# NUC100BN_v1 register map
File version: 1.0
Registers are 32-bit, read-write, reset 0x0 unless marked. A register's access mark holds for its fields unless they carry their own. Offsets are from the block's base; [hi:lo] are bit positions; 'fields as' and 'values as' point back to an identical list.

## SPI0 — SPI Register Map
Base 0x40030000
Same registers: SPI1 0x40034000, SPI2 0x40130000, SPI3 0x40134000
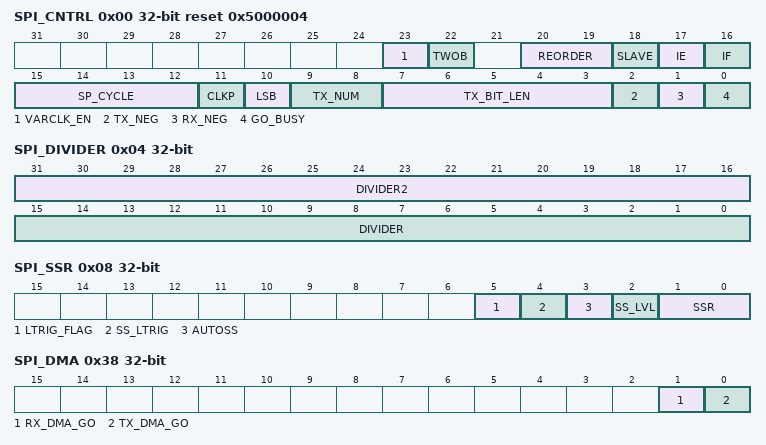
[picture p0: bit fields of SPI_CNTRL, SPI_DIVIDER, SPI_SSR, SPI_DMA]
0x00 SPI_CNTRL reset 0x5000004 — Control and Status Register
  [23] VARCLK_EN — Variable Clock Enable (Master Only). Note: When this VARCLK_EN bit is enabled, the setting of TX_BIT_LEN must be programmed as 0x10 (16-bit mode)
    0=Serial clock output frequency is fixed and decided only by the value of DIVIDER; 1=Serial clock output frequency is variable. The output frequency is decided by the value of VARCLK, DIVIDER, and DIVIDER2
  [22] TWOB — Two Bits Transfer Mode Active. Note: When TWOB is enabled, the serial transmitted 2-bit data output are from SPI_TX1/0, and the received 2-bit data input are put in SPI_RX1/0. Note: When TWOB is enabled, the setting of TX_NUM must be programmed as 0x00.
    0=Two-bit Transfer mode Disabled; 1=Two-bit Transfer mode Enabled
  [20:19] REORDER — Reorder Mode Select. Note: Byte reorder function is only available when TX_BIT_LEN is defined as 16, 24, and 32 bits. In Slave mode with level-trigger configuration, if the byte suspend function is enabled, the slave select pin must be kept at active state during the successive four bytes transfer.
    0=Both byte reorder and byte suspend functions Disabled; 1=Byte reorder function Enabled, and a byte suspend interval (2~17 SPICLK cycles) inserted among each byte. The setting of TX_BIT_LEN must be configured as 0x00. (32 bits/word); 2=Byte reorder function Enabled, but byte suspend function Disabled; 3=Byte reorder function Disabled, but a suspend interval (2~17 SPICLK cycles) inserted among each byte. The setting of TX_BIT_LEN must be configured as 0x00. (32 bits/word)
  [18] SLAVE — Slave Mode Enable Bit
    0=Master mode; 1=Slave mode
  [17] IE — Interrupt Enable
    0=SPI Interrupt Disabled; 1=SPI Interrupt Enabled
  [16] IF — Interrupt Flag. Note: This bit will be cleared by writing 1 to itself.
    0=Indicates the transfer dose not finish; 1=Indicates the transfer is done
  [15:12] SP_CYCLE — Suspend Interval (Master Only)
  [11] CLKP — Clock Polarity
    0=SPICLK idle low; 1=SPICLK idle high
  [10] LSB — LSB First
    0=MSB is transmitted/received first (which bit in SPI_TX0/1 and SPI_RX0/1 register that is depends on the TX_BIT_LEN field); 1=LSB is sent first on the line (bit 0 of SPI_TX0/1), and the first bit received from the line will be put in the LSB position in the RX register (bit 0 of SPI_RX0/1)
  [9:8] TX_NUM — Numbers of Transmit/Receive Word. This field specifies how many transmit/receive word numbers should be executed in one transfer. Note: In Slave mode with level-trigger configuration, if TX_NUM is set to 01, the slave select pin must be kept at active state during the successive data transfer.
    0=Only one transmit/receive word will be executed in one transfer; 1=Two successive transmit/receive words will be executed in one transfer. (burst mode)
  [7:3] TX_BIT_LEN — Transmit Bit Length. This field specifies how many bits can be transmitted / received in one transaction. The minimum bit length is 8 bits and can up to 32 bits.
  [2] TX_NEG — Transmit At Negative Edge
    0=Transmitted data output signal is changed at the rising edge of SPICLK; 1=Transmitted data output signal is changed at the falling edge of SPICLK
  [1] RX_NEG — Receive At Negative Edge
    0=Received data input signal is latched at the rising edge of SPICLK; 1=Received data input signal is latched at the falling edge of SPICLK
  [0] GO_BUSY — Go and Busy Status. During the data transfer, this bit keeps the value of 1. As the transfer is finished, this bit will be cleared automatically. Note: All registers should be set before writing 1 to this GO_BUSY bit.
    0=Stop data transfer if SPI is transferring; 1=In Master mode, start the SPI data transfer; in Slave mode, writing 1 to this bit indicates that the slave is ready to communicate with a master
0x04 SPI_DIVIDER — Clock Divider Register (Master Only)
  [31:16] DIVIDER2 — Clock Divider 2 (Master Only). The value in this field is the 2nd frequency divider for generating the serial clock on the output SPICLK. The desired frequency is obtained according to the following equation: . If VARCLK_EN is cleared to 0, this setting is unmeaning.
  [15:0] DIVIDER — Clock Divider 1 (Master Only). The value in this field is the frequency divider for generating the serial clock on the output SPICLK. The desired frequency is obtained according to the following equation: . In Slave mode, the period of SPI clock driven by a master shall equal or over 5 times the period of PCLK. In other words, the maximum frequency of SPI clock is the fifth of the frequency of slave's PCLK.
0x08 SPI_SSR — Slave Select Register
  [5] LTRIG_FLAG — Level Trigger Accomplish Flag. When the SS_LTRIG bit is set in Slave mode, this bit can be read to indicate the received bit number is met the requirement or not. Note: This bit is READ only.
    0=Transaction number or the transferred bit length of one transaction does not meet the specified requirements; 1=Transaction number and the transferred bit length met the specified requirements which defined in TX_NUM and TX_BIT_LEN
  [4] SS_LTRIG — Slave Select Level Trigger Enable Bit (Slave only)
    0=Input slave select signal is edge-trigger. This is the default value. It depends on SS_LVL to decide the signal is active at falling-edge or rising-edge; 1=Slave select signal will be level-trigger. It depends on SS_LVL to decide the signal is active low or active high
  [3] AUTOSS — Automatic Slave Select Enable Bit (Master only)
    0=If this bit is cleared, slave select signals will be asserted/de-asserted by setting /clearing related bits in SSR[1:0]; 1=If this bit is set, SPISSx0/1 signals will be generated automatically. It means that device/slave select signal, which is set in SSR[1:0], will be asserted by the SPI controller when transmit/receive is started by setting GO_BUSY, and will be de-asserted after each transmit/receive is finished
  [2] SS_LVL — Slave Select Active Level. It defines the active status of slave select signal (SPISSx0/1).
    0=Slave select signal SPISSx0/1 is active at low-level/falling-edge; 1=Slave select signal SPISSx0/1 is active at high-level/rising-edge
  [1:0] SSR — Slave Select Control Bits (Master only). If AUTOSS bit is cleared, writing 1 to any bit location of this field sets the proper SPISSx0/1 line to an active state and writing 0 sets the line back to inactive state. If AUTOSS bit is set, writing 0 to any bit location of this field will keep the corresponding SPISSx0/1 line at inactive state; writing 1 to any bit location of this field will select appropriate SPISSx0/1 line to be automatically driven to active state for the duration of the transmit/receive, and will be driven to inactive state for the rest of the time. The active state of SPISSx0/1 is specified in SS_LVL. Note: SPISSx0 is also defined as slave select input in Slave mode.
0x10 SPI_RX0 ro — Data Receive Register 0
  [31:0] RX — Data Receive Register. The Data Receive Registers hold the value of received data of the last executed transfer. Valid bits depend on the transmit bit length field in the SPI_CNTRL register. For example, if TX_BIT_LEN is set to 0x08 and TX_NUM is set to 0x0, bit RX0[7:0] holds the received data. The values of the other bits are unknown. Note: The Data Receive Registers are read only.
0x14 SPI_RX1 ro — Data Receive Register 1
  fields as SPI_RX0
0x20 SPI_TX0 wo — Data Transmit Register 0
  [31:0] TX — Data Transmit Register. The Data Transmit Registers hold the data to be transmitted in the next transfer. The valid bits depend on the transmit bit length field in the CNTRL register. For example, if TX_BIT_LEN is set to 0x08 and the TX_NUM is set to 0x0, the bit TX0[7:0] will be transmitted in next transfer. If TX_BIT_LEN is set to 0x00 and TX_NUM is set to 0x1, the SPI controller will perform two 32-bit transmit/receive successive using the same setting. The transmission sequence is TX0[31:0] first and then TX1[31:0].
0x24 SPI_TX1 wo — Data Transmit Register 1
  fields as SPI_TX0
0x34 SPI_VARCLK reset 0x7FFF87 — Variable Clock Pattern Register
  [31:0] VARCLK — Variable Clock Pattern. The value in this field is the frequency patterns of the SPI clock. If the bit pattern of VARCLK is '0', the output frequency of SPICLK is in accordance with the value of DIVIDER. If the bit patterns of VARCLK are '1', the output frequency of SPICLK is in accordance with the value of DIVIDER2. Refer to register SPI_DIVIDER. Refer to the Variable Serial Clock Frequency paragraph for more detailed description.
0x38 SPI_DMA — SPI DMA Control Register
  [1] RX_DMA_GO — Receive DMA Start. Setting this bit to 1 will start the receive PDMA process. SPI controller will issue request to PDMA controller automatically. Hardware will clear this bit to 0 automatically after PDMA transfer done.
  [0] TX_DMA_GO — Transmit DMA Start. Setting this bit to 1 will start the transmit PDMA process. SPI controller will issue request to PDMA controller automatically. If using PDMA mode to transfer data, remember not to set GO_BUSY bit of SPI_CNTRL register. The DMA controller inside SPI controller will set it automatically whenever necessary. Hardware will clear this bit to 0 automatically after PDMA transfer done. Note: In DMA mode, the burst mode is not supported.
